# A31G314 register map
Vendor: ABOV Semiconductor Co., Ltd.; Series: A31G314; File version: 1.0
CPU: CM0PLUS r0p1, little endian, no MPU, no FPU, VTOR, 2 interrupt priority bits
Registers are 32-bit, read-write, reset 0x0 unless marked. A register's access mark holds for its fields unless they carry their own. Offsets are from the block's base; [hi:lo] are bit positions.

## DAC — 12-BIT D/A CONVERTER
Base 0x40003450
0x00 DR — D/A Converter Data Register
  [15:0] DACDR — D/A Converter Data (16-bit) The DACDR[15:0] is a binary format.
0x04 BR ro — D/A Converter Buffer Register
  [15:0] DACBR — D/A Converter Buffer Data (16-bit) The DACBR[15:0] is a binary format.
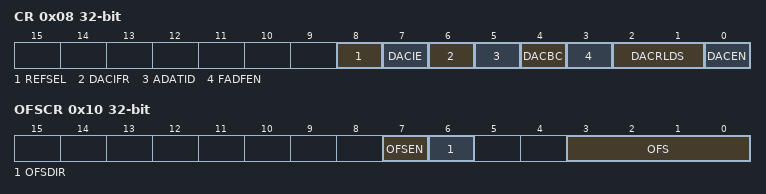
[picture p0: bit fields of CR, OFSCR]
0x08 CR — D/A Converter Control Register
  [8] REFSEL — DAC Reference Selection 0:AVDD, 1: DAVREF Pin
  [7] DACIE — Enable or Disable D/AC Interrupt
  [6] DACIFR — When D/AC Interrupt occurs, this bit becomes '1'. The flag is cleared only by writing a '0' to the bit. So, the flag should be cleared by software. This interrupt is for a result that the DACDRH register automatically increments to "800xH" or decrements to "000xH". Write '1' has no effect.
  [5] ADATID — Automatically D/A Converter Data Increment/Decrement
  [4] DACBC — D/A Converter Buffer Clear
  [3] FADFEN — Decoder Result Output Data Fetch Enable
  [2:1] DACRLDS — D/A Converter Reload Selection. These bits select a reload signal to load data from D/AC data register to buffer.
  [0] DACEN — D/A Converter Enable Bit
0x0C PGSR — Programmable Gain Control Register
  [3:0] PSG — Programmable Gain Selection
0x10 OFSCR — D/A Converter Offset Control Register
  [7] OFSEN — D/AC Offset Control Enable Bit
  [6] OFSDIR — D/AC Offset Direction Selection Bit
  [3:0] OFS — D/AC Offset Value

## CMP — COMPARATOR
Base 0x40003420
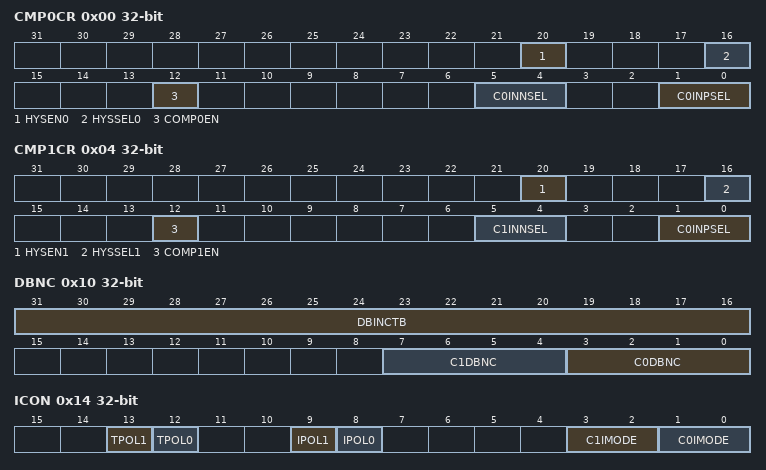
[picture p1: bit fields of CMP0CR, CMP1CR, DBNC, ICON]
0x00 CMP0CR — Comparator 0 Control Register
  [20] HYSEN0 — Comparator Hysteresis Enable 0: Disable Hysteresis 1: Enable Hysteresis
  [16] HYSSEL0 — Comparator Hysteresis Select 0: 5mV Hysteresis 1: 20mV Hysteresis
  [12] COMP0EN — Comparator Enable bits 0: Disable Comparator 1: Enable Comparator
  [5:4] C0INNSEL — Comparator Reference(input -) Selection bit 00: CREF0 01: BGR 1V 10: DAC OUT 11: CREF1
  [1:0] C0INPSEL — Comparator Input(input -) Selection bit 00: CP0 01: CP1B 10: CP1C 11: ADC MUX OUT
0x04 CMP1CR — Comparator 1 Control Register
  [20] HYSEN1 — Comparator Hysteresis Enable 0: Disable Hysteresis 1: Enable Hysteresis
  [16] HYSSEL1 — Comparator Hysteresis Select 0: 5mV Hysteresis 1: 20mV Hysteresis
  [12] COMP1EN — Comparator Enable bits 0: Disable Comparator 1: Enable Comparator
  [5:4] C1INNSEL — Comparator Reference(input -) Selection bit 00: CREF1 01: BGR 1V 10: DAC OUT 11: CREF0
  [1:0] C0INPSEL — Comparator Input(input -) Selection bit 00: CP1A 01: CP1B 10: CP1C 11: ADC MUX OUT
0x10 DBNC — Comparator Debounce Register
  [31:16] DBINCTB — Debounce time base counter System clock/(DBNCTB *2) becomes shift clock of debounce logic When DBNCTB is 0, system clock would be debounce clock.
  [7:4] C1DBNC — Debounce shift Selection When it is 0x0, debounce function is disable Shift number of debounce logic is (C1DBNC + 1) when C1DBNC is more than 1
  [3:0] C0DBNC — Debounce shift Selection When it is 0x0, debounce function is disable Shift number of debounce logic is (C1DBNC + 1) when C1DBNC is more than 1
0x14 ICON — Comparator Interrupt Control Register
  [13] TPOL1 — Comparator Trigger output polarity(to trigger other IP) 0: output normal (comparator out high activates trigger) 1: output inverted (XOR)
  [12] TPOL0 — Comparator Trigger output polarity(to trigger other IP) 0: output normal (comparator out high activates trigger) 1: output inverted (XOR)
  [9] IPOL1 — Comparator 1 interrupt polarity(level mode) 0: interrupt at comparator out high 1: interrupt at comparator out low
  [8] IPOL0 — Comparator 0 interrupt polarity(level mode) 0: interrupt at comparator out high 1: interrupt at comparator out low
  [3:2] C1IMODE — Comparator 1 Interrupt Flag bit. 00: level interrupt (by IPOL1) 01: rising edge interrupt 10: falling edge interrupt 11: both edge interrupt A/D Converter Prescaler Data bits.
  [1:0] C0IMODE — Comparator 0 Interrupt Flag bit. 00: level interrupt (by IPOL0) 01: rising edge interrupt 10: falling edge interrupt 11: both edge interrupt A/D Converter Prescaler Data bits.
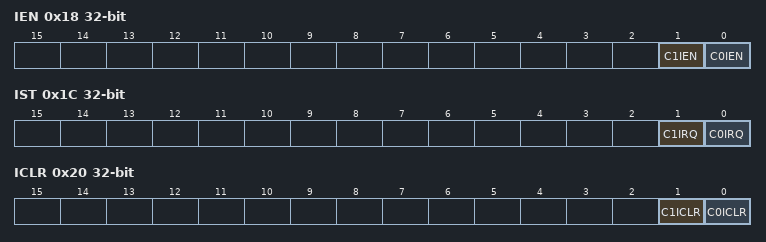
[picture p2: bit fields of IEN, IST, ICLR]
0x18 IEN — Comparator Interrupt Enable Register
  [1] C1IEN — Comparator 1 Enable 0: Disable 1: Enable
  [0] C0IEN — Comparator 0 Enable 0: Disable 1: Enable
0x1C IST ro — Comparator Interrupt Status Register
  [1] C1IRQ — Comparator 1 interrupt Status 0: No Comparator Interrupt 1: Comparator Interrupt asserted
  [0] C0IRQ — Comparator 0 interrupt Status 0: No Comparator Interrupt 1: Comparator Interrupt asserted
0x20 ICLR — Comparator Interrupt Clear Register
  [1] C1ICLR — Comparator 1 Interrupt Clear (write "1" to clear C1IRQ)
  [0] C0ICLR — Comparator 0 Interrupt Clear (write "1" to clear C0IRQ)
